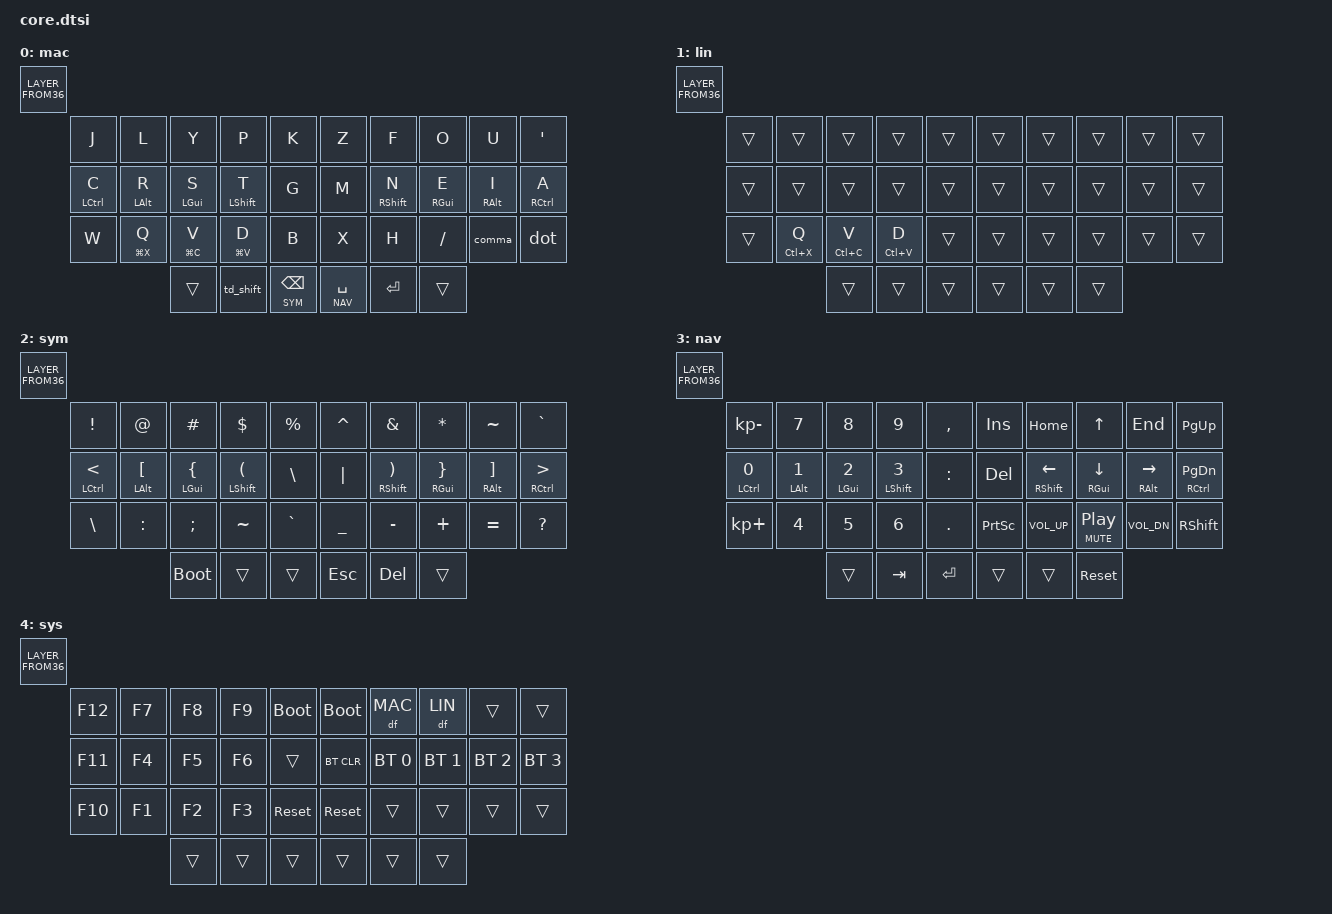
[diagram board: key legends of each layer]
/*
 * Copyright (c) 2022 The ZMK Contributors
 *
 * SPDX-License-Identifier: MIT
 */

/* #ifdef ENCODER */
/*   #define WRAPPED_ENCODER ENCODER "," */
/*   #ifndef ENCODER &none */
/* #endif */
/* #ifndef ENCODER */
/*   #define ENCODER "" */
/*   #define WRAPPED_ENCODER ENCODER */
/* #endif */

#ifndef EXTRA_BINDINGS
  #define EXTRA_BINDINGS ""
#endif

#define MAC 0
#define LIN 1
#define SYM 2
#define NAV 3 // numpad and navigation
#define SYS 4 // fn, bluetooth, media controls
// #define mse 5

#include <behaviors.dtsi>
#include <dt-bindings/zmk/keys.h>
#include <dt-bindings/zmk/bt.h>
#include "elpekenin/behaviors.dtsi"

// NOTE: remember to put this in the board keymap file
/* / { */
/*   chosen { */
/*     //zmk,matrix_transform = &default_transform; */
/*     zmk,matrix_transform = &five_column_transform; */
/*   }; */
/* }; */


// TODO: add layer defs to the layout header files

/ {
    behaviors {
        // sticky that applies just before the next keystroke
        skq: sticky_key_quick_release {
          compatible = "zmk,behavior-sticky-key";
          #binding-cells = <1>;
          bindings = <&kp>;
          release-after-ms = <1000>;
          quick-release;
          /* ignore-modifiers; */
          // this was wrapping my semi colon override in another shift, causing colon
        };

        shift: hold_tap_shift {
            compatible = "zmk,behavior-hold-tap";
            bindings = <&kp>, <&skq>;

            #binding-cells = <2>;
            tapping-term-ms = <150>;
            flavor = "tap-preferred";
        };

        td_shift: tap_dance_shift_caps_word {
            compatible = "zmk,behavior-tap-dance";
            bindings = <&shift RSHIFT LSHIFT>, <&caps_word>;

            #binding-cells = <0>;
            tapping-term-ms = <200>;
        };

        hrm: homerow_mods {
            compatible = "zmk,behavior-hold-tap";
            bindings = <&kp>, <&kp>;

            #binding-cells = <2>;
            tapping-term-ms = <200>;
            require-prior-idle-ms = <125>;
            quick-tap-term = <150>;
            flavor = "tap-preferred";
        };

        hrs: homerow_shift {
            compatible = "zmk,behavior-hold-tap";
            bindings = <&kp>, <&kp>;

            #binding-cells = <2>;
            tapping-term-ms = <150>;
            flavor = "balanced";
        };

        lh: layer_hold {
          compatible = "zmk,behavior-hold-tap";
          bindings = <&mo>, <&kp>;

          #binding-cells = <2>;
          tapping-term-ms = <200>;
          flavor = "hold-preferred";
        };

        bspc: bspc_del_on_shift {
            compatible = "zmk,behavior-mod-morph";
            bindings = <&kp BSPC>, <&kp DEL>;

            #binding-cells = <0>;
            mods = <(MOD_LSFT|MOD_RSFT)>;
        };

        // the following only USES one argument but requires 2, so pass in the layer as the
        // first param and a dummy value like 0 as second
        lhbs: layer_hold_bspc_override {
            compatible = "zmk,behavior-hold-tap";
            /* bindings = <&mo>, <&bspc>; */
            bindings = <&mo>, <&kp>;

            #binding-cells = <2>;
            tapping-term-ms = <200>;
        };

        space: space_tab_on_shift {
            compatible = "zmk,behavior-mod-morph";
            bindings = <&kp SPACE>, <&kp TAB>;

            #binding-cells = <0>;
            mods = <(MOD_LSFT)>;
        };

        ltsp: layer_tap_space_override {
            compatible = "zmk,behavior-hold-tap";
            bindings = <&mo>, <&kp>;

            #binding-cells = <2>;
            tapping-term-ms = <200>;
            flavor = "tap-preferred";
        };

        comma: comma_semicolon_on_shift {
            compatible = "zmk,behavior-mod-morph";
            bindings = <&kp COMMA>, <&kp SEMI>;

            #binding-cells = <0>;
            mods = <(MOD_LSFT|MOD_RSFT)>;
        };

        dot: dot_colon_on_shift {
            compatible = "zmk,behavior-mod-morph";
            bindings = <&kp DOT>, <&kp COLON>;

            #binding-cells = <0>;
            mods = <(MOD_LSFT|MOD_RSFT)>;
        };

        lp: long_press {
            compatible = "zmk,behavior-hold-tap";
            bindings = <&kp>, <&kp>;

            #binding-cells = <2>;
            tapping-term-ms = <150>;
            flavor = "balanced";
        };
    };

    combos {
        compatible = "zmk,combos";

        escape {
            bindings = <&kp ESC>;
            key-positions = <LM3 LM2>;
            require-prior-idle-ms = <40>;
            timeout-ms = <25>;
            // layers = <0 1>;
        };

        enter {
            bindings = <&kp ENTER>;
            key-positions = <RM2 RM3>;
            // key-positions = <27 28>;
            require-prior-idle-ms = <40>;
            timeout-ms = <20>;
        };

        tab {
            bindings = <&kp TAB>;
            key-positions = <LM2 LM1>;
            require-prior-idle-ms = <40>;
            timeout-ms = <20>;
        };

        caps {
            bindings = <&kp CAPS>;
            key-positions = <RT1 RT2 RT3>;
            require-prior-idle-ms = <40>;
            timeout-ms = <20>;
        };

        sl_sys {
            bindings = <&sl SYS>;
            key-positions = <LT1 LT2 LT3>;
            require-prior-idle-ms = <40>;
            timeout-ms = <20>;
        };

        //*** OS specific combos ***//
        // mac combos
        /* copy { */
        /*     bindings = <&kp LG(C)>; */
        /*     key-positions = <LB3 LB2>; */
        /*     layers = <0>; */
        /* }; */
        /**/
        /* paste { */
        /*     bindings = <&kp LG(V)>; */
        /*     key-positions = <LB2 LB1>; */
        /*     layers = <0>; */
        /* }; */
        /**/
        /* cut { */
        /*     bindings = <&kp LG(X)>; */
        /*     key-positions = <LB3 LB1>; */
        /*     layers = <0>; */
        /* }; */

        back_word {
            bindings = <&kp LA(BSPC)>;
            key-positions = <LM3 LM1>;
            require-prior-idle-ms = <50>;
            timeout-ms = <20>;
            layers = <0>;
        };

        del_word {
            bindings = <&kp LA(DEL)>;
            key-positions = <RM1 RM3>;
            require-prior-idle-ms = <50>;
            timeout-ms = <20>;
            layers = <0>;
        };

        undo {
            bindings = <&kp LG(Z)>;
            key-positions = <RT1 RT2>;
            require-prior-idle-ms = <50>;
            timeout-ms = <20>;
            layers = <0>;
        };

        redo {
            bindings = <&kp LG(LS(Z))>;
            key-positions = <RT2 RT3>;
            require-prior-idle-ms = <50>;
            timeout-ms = <20>;
            layers = <0>;
        };

        // linux combos
        /* copy_lin { */
        /*     bindings = <&kp LC(C)>; */
        /*     key-positions = <LB3 LB2>; */
        /*     layers = <1>; */
        /* }; */
        /**/
        /* paste_lin { */
        /*     bindings = <&kp LC(V)>; */
        /*     key-positions = <LB2 LB1>; */
        /*     layers = <1>; */
        /* }; */
        /**/
        /* cut_lin { */
        /*     bindings = <&kp LC(X)>; */
        /*     key-positions = <LB3 LB1>; */
        /*     layers = <1>; */
        /* }; */

        back_word_lin {
            bindings = <&kp LC(BSPC)>;
            key-positions = <LM3 LM1>;
            require-prior-idle-ms = <50>;
            timeout-ms = <20>;
            layers = <1>;
        };

        del_word_lin {
            bindings = <&kp LC(DEL)>;
            key-positions = <RM1 RM3>;
            require-prior-idle-ms = <50>;
            timeout-ms = <20>;
            layers = <1>;
        };

        undo_lin {
            bindings = <&kp LC(Z)>;
            key-positions = <RT1 RT2>;
            require-prior-idle-ms = <50>;
            timeout-ms = <20>;
            layers = <1>;
        };

        redo_lin {
            bindings = <&kp LC(Y)>;
            key-positions = <RT2 RT3>;
            require-prior-idle-ms = <50>;
            timeout-ms = <20>;
            layers = <1>;
        };

    };

    keymap {
        compatible = "zmk,keymap";

        mac {
            label = "mac";
            //╭──────────┬──────────┬──────────┬──────────┬──────────╮     ╭──────────┬──────────┬──────────┬──────────┬──────────╮
            //│  J       │  L       │  Y       │  P       │  K       │     │  Z       │  F       │  O       │  U       │  '"      │
            //├──────────┼──────────┼──────────┼──────────┼──────────┤     ├──────────┼──────────┼──────────┼──────────┼──────────┤
            //│  C       │  R       │  S       │  T       │  G       │     │  M       │  N       │  E       │  I       │  A       │
            //├──────────┼──────────┼──────────┼──────────┼──────────┤     ├──────────┼──────────┼──────────┼──────────┼──────────┤
            //│  W       │  Q       │  V       │  D       │  B       │     │  X       │  H       │  / ?     │   , ;    │  . :     │
            //╰──────────┴──────────┴──────────┼──────────┼──────────┤     ├──────────┼──────────┼──────────┴──────────┴──────────╯
            //                      │          │          │          │     │          │          │          │
            //                      ╰──────────┴──────────┴──────────╯     ╰──────────┴──────────┴──────────╯

            bindings = <LAYER_FROM36( \
             &kp J,      &kp L,      &kp Y,      &kp P,      &kp K,                              &kp Z,      &kp F,      &kp O,      &kp U,      &kp SQT, \
        &hrm LCTRL C,  &hrm LALT R,  &hrm LGUI S,  &hrs LSHFT T,  &kp G,                         &kp M,   &hrs RSHFT N,  &hrm RGUI E,  &hrm RALT I,  &hrm RCTRL A, \
             &kp W,    &lp LG(X) Q,  &lp LG(C) V,  &lp LG(V) D,   &kp B,                         &kp X,         &kp H,          &kp FSLH,   &comma,  &dot, \
                                   &trans,   &td_shift,       &lhbs SYM BSPC,                      &ltsp NAV SPACE,     &kp ENTER,      &trans
            )>;
        };

        lin {
            label = "lin";
            bindings = <LAYER_FROM36( \
             &trans,      &trans,      &trans,      &trans,      &trans,                             &trans,      &trans,      &trans,      &trans,      &trans, \
             &trans,  &trans,  &trans,  &trans,  &trans,                     &trans,   &trans,  &trans,  &trans,  &trans, \
             &trans,      &lp LC(X) Q, &lp LC(C) V, &lp LC(V) D,      &trans,                             &trans,      &trans,      &trans,   &trans,  &trans, \
                                   &trans,   &trans,       &trans,                          &trans,     &trans,      &trans
            )>;
        };

        sym {
            label = "sym";
        //╭──────────┬──────────┬──────────┬──────────┬──────────╮      ╭──────────┬──────────┬──────────┬──────────┬──────────╮
        //│  !       │  @       │   #      │    $     │     %    │      │  ^       │   &      │  *       │  ~       │  `       │
        //├──────────┼──────────┼──────────┼──────────┼──────────┤      ├──────────┼──────────┼──────────┼──────────┼──────────┤
        //│  <       │  [       │  {       │  (       │  \       │      │  |       │  )       │  }       │  ]       │  >       │
        //├──────────┼──────────┼──────────┼──────────┼──────────┤      ├──────────┼──────────┼──────────┼──────────┼──────────┤
        //│   \      │ ~        │ `~       │  "       │ '"       │      │  _       │   -      │  +       │  =       │  ?       │
        //╰──────────┴──────────┴──────────┼──────────┼──────────┤      ├──────────┼──────────┼──────────┴──────────┴──────────╯
        //                      │          │          │          │      │          │          │          │
        //                      ╰──────────┴──────────┴──────────╯      ╰──────────┴──────────┴──────────╯

            bindings = <LAYER_FROM36( \
              &kp EXCLAMATION,  &kp AT,     &kp HASH,   &kp DOLLAR,  &kp PERCENT,    &kp CARET,  &kp AMPS,   &kp STAR,   &kp TILDE,  &kp GRAVE, \
              &hrm LCTRL LESS_THAN,  &hrm LALT LBKT,  &hrm LGUI LBRC,  &hrs LSHFT LPAR,   &kp BSLH,  &kp PIPE,  &hrs RSHFT RPAR,  &hrm RGUI RBRC,  &hrm RALT RBKT,  &hrm RCTRL GREATER_THAN, \
              &kp BSLH,      &kp COLON,   &kp SEMI, &kp TILDE,  &kp GRAVE,         &kp UNDER,      &kp MINUS,    &kp PLUS,    &kp EQUAL,  &kp QMARK, \
                                      &bootloader,     &trans,      &trans,         &kp ESC,  &kp DEL,  &trans
            )>;
        };

        nav {
        //╭──────────┬──────────┬──────────┬──────────┬──────────╮      ╭──────────┬──────────┬──────────┬──────────┬──────────╮
        //│    -     │     7    │     8    │     9    │    ,     │      │  INS     │  HOME    │    UP    │  END     │  PG UP   │
        //├──────────┼──────────┼──────────┼──────────┼──────────┤      ├──────────┼──────────┼──────────┼──────────┼──────────┤
        //│     0    │     1    │     2    │    3     │    :     │      │   DEL    │  LEFT    │  DOWN    │  RIGHT   │  PG DN   │
        //├──────────┼──────────┼──────────┼──────────┼──────────┤      ├──────────┼──────────┼──────────┼──────────┼──────────┤
        //│     +    │     4    │     5    │    6     │    .     │      │  PRINT   │  VOL UP  │    ⏯     │  VOL DN  │   SHIFT  │
        //╰──────────┴──────────┴──────────┼──────────┼──────────┤      ├──────────┼──────────┼──────────┴──────────┴──────────╯
        //                      │          │          │          │      │          │          │          │
        //                      ╰──────────┴──────────┴──────────╯      ╰──────────┴──────────┴──────────╯
            label = "nav";
            bindings = <LAYER_FROM36( \
              &kp KP_MINUS,    &kp N7,      &kp N8,      &kp N9,   &kp COMMA,          &kp INS,  &kp HOME,    &kp UP,     &kp END,   &kp PG_UP, \
              &hrm LCTRL N0,   &hrm LALT N1,  &hrm LGUI N2,     &hrs LSHFT N3,     &kp COLON,           &kp DEL,  &hrm RSHFT LEFT,  &hrm RGUI DOWN,    &hrm RALT RIGHT,   &hrm RCTRL PG_DN, \
              &kp KP_PLUS,  &kp N4,    &kp N5,      &kp N6,   &kp DOT,            &kp PSCRN, &kp C_VOL_UP,   &lp C_MUTE C_PLAY_PAUSE, &kp C_VOL_DN,  &kp RSHFT, \
                                    &trans,  &kp TAB,     &kp ENTER,         &trans,      &trans,   &sys_reset
            )>;
        };

        sys {
        // TODO: consider matching the numpad layer in this arrangement
        //╭──────────┬──────────┬──────────┬──────────┬──────────╮      ╭──────────┬──────────┬──────────┬──────────┬──────────╮
        //│    F12   │    F7    │    F8    │    F9    │          │      │          │    mac   │  linux   │          │          │
        //├──────────┼──────────┼──────────┼──────────┼──────────┤      ├──────────┼──────────┼──────────┼──────────┼──────────┤
        //│    F11   │    F4    │    F5    │    F6    │          │      │          │          │          │          │          │
        //├──────────┼──────────┼──────────┼──────────┼──────────┤      ├──────────┼──────────┼──────────┼──────────┼──────────┤
        //│    F10   │    F1    │    F2    │    F3    │          │      │          │          │          │          │          │
        //╰──────────┴──────────┴──────────┼──────────┼──────────┤      ├──────────┼──────────┼──────────┴──────────┴──────────╯
        //                      │          │          │          │      │          │          │          │
        //                      ╰──────────┴──────────┴──────────╯      ╰──────────┴──────────┴──────────╯
        // TODO: create a pinky layer tap on period to get to function layer
        // TODO: create a pinky layer tap on W to get to bt/lighting/system layer
        // find somewhere for c_vol_up, c_vol_down, c_mute, c_bri_up, c_bri_dn, c_play_pause (c_pp)?
        // consider putting the corresponding bt disc below each bt profile? if needed.
            display-name = "sys";
            bindings = <LAYER_FROM36( \
               &kp F12,    &kp F7,     &kp F8,     &kp F9,       &bootloader,    &bootloader,     &df MAC,     &df LIN,      &trans,     &trans, \
               &kp F11,    &kp F4,     &kp F5,     &kp F6,       &trans,         &bt BT_CLR, &bt BT_SEL 0, &bt BT_SEL 1, &bt BT_SEL 2, &bt BT_SEL 3, \
               &kp F10,    &kp F1,     &kp F2,     &kp F3,       &sys_reset,     &sys_reset,     &trans,     &trans,     &trans,     &trans, \
                                       &trans,     &trans,     &trans,            &trans,     &trans,     &trans
            )>;
        };
    };
};
